# STM32F427 register map
File version: 1.7
CPU: CM4 r0p1, little endian, MPU, FPU, 4 interrupt priority bits
Registers are 32-bit, read-write, reset 0x0 unless marked. A register's access mark holds for its fields unless they carry their own. Offsets are from the block's base; [hi:lo] are bit positions; lines under a group give offsets from that group; {n}, {i} and the like mark numbered series.

## OTG_FS_PWRCLK — USB on the go full speed
Base 0x50000E00
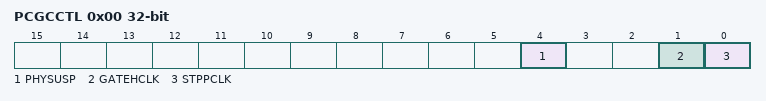
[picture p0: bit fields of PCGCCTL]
0x00 PCGCCTL — OTG_FS power and clock gating control register (OTG_FS_PCGCCTL)
  [4] PHYSUSP — PHY Suspended
  [1] GATEHCLK
  [0] STPPCLK — Stop PHY clock

## EXTI — External interrupt/event controller
Base 0x40013C00
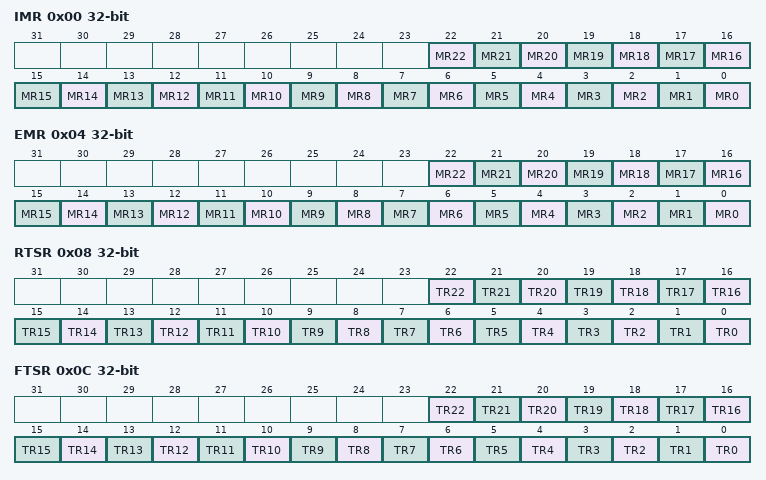
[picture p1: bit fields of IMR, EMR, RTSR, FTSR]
0x00 IMR — Interrupt mask register (EXTI_IMR)
  [n] MR{n} (n=0..22) — Interrupt Mask on line {n}
    0=Masked (Interrupt request line is masked); 1=Unmasked (Interrupt request line is unmasked)
0x04 EMR — Event mask register (EXTI_EMR)
  [n] MR{n} (n=0..22) — Event Mask on line {n}
    0=Masked (Event request line is masked); 1=Unmasked (Event request line is unmasked)
0x08 RTSR — Rising Trigger selection register (EXTI_RTSR)
  [n] TR{n} (n=0..22) — Rising trigger event configuration of line {n}
    0=Disabled (Rising edge trigger is disabled); 1=Enabled (Rising edge trigger is enabled)
0x0C FTSR — Falling Trigger selection register (EXTI_FTSR)
  [n] TR{n} (n=0..22) — Falling trigger event configuration of line {n}
    0=Disabled (Falling edge trigger is disabled); 1=Enabled (Falling edge trigger is enabled)
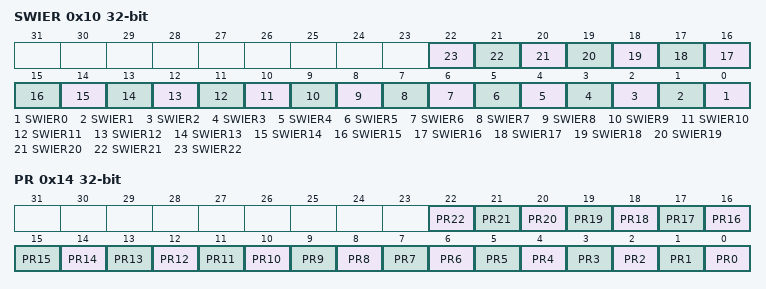
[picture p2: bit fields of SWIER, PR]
0x10 SWIER — Software interrupt event register (EXTI_SWIER)
  [n] SWIER{n} (n=0..22) — Software Interrupt on line {n}
    on write: 1=Pend (Generates an interrupt request)
0x14 PR — Pending register (EXTI_PR)
  [n] PR{n} (n=0..22) write-1-clears — Pending bit {n}
    on read: 0=NotPending (No trigger request occurred); 1=Pending (Selected trigger request occurred) | on write: 1=Clears pending bit

## OTG_HS_HOST — USB on the go high speed
Base 0x40040400
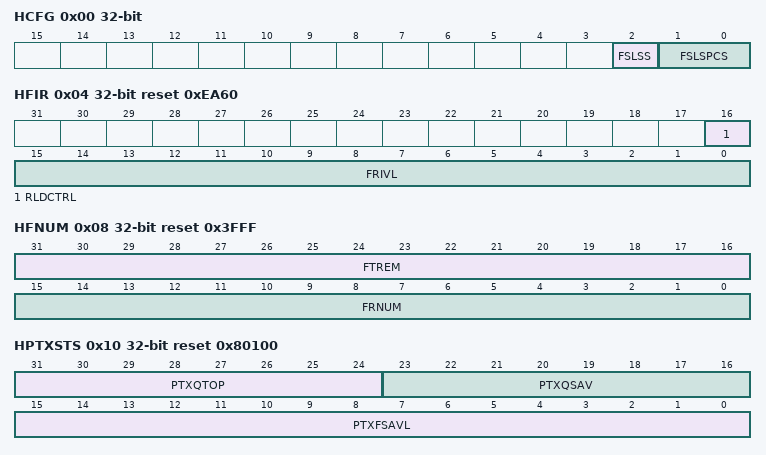
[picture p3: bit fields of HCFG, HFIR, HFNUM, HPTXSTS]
0x00 HCFG access per field — OTG_HS host configuration register
  [2] FSLSS ro — FS- and LS-only support
  [1:0] FSLSPCS rw — FS/LS PHY clock select
0x04 HFIR reset 0xEA60 — OTG_HS Host frame interval register
  [16] RLDCTRL — Reload control
  [15:0] FRIVL — Frame interval
0x08 HFNUM ro reset 0x3FFF — OTG_HS host frame number/frame time remaining register
  [31:16] FTREM — Frame time remaining
  [15:0] FRNUM — Frame number
0x10 HPTXSTS access per field reset 0x80100 — OTG_HS_Host periodic transmit FIFO/queue status register
  [31:24] PTXQTOP ro — Top of the periodic transmit request queue
  [23:16] PTXQSAV ro — Periodic transmit request queue space available
  [15:0] PTXFSAVL rw — Periodic transmit data FIFO space available
0x14 HAINT ro — OTG_HS Host all channels interrupt register
  [15:0] HAINT — Channel interrupts
0x18 HAINTMSK — OTG_HS host all channels interrupt mask register
  [15:0] HAINTM — Channel interrupt mask
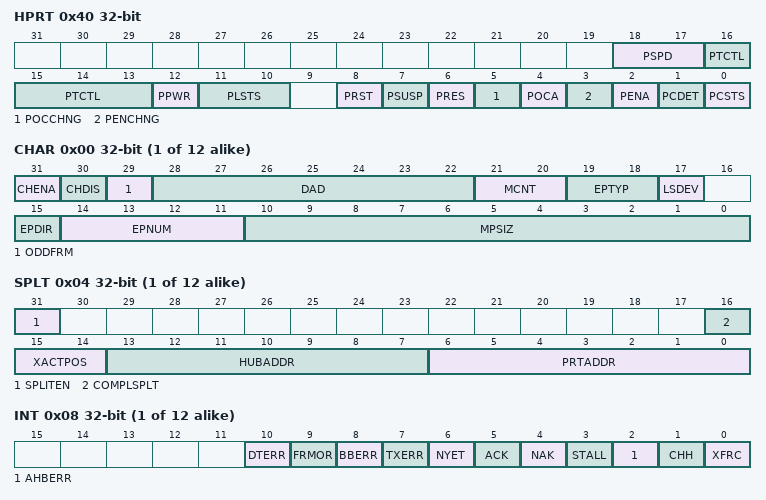
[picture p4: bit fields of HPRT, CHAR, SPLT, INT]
0x40 HPRT access per field — OTG_HS host port control and status register
  [18:17] PSPD ro — Port speed
  [16:13] PTCTL rw — Port test control
  [12] PPWR rw — Port power
  [11:10] PLSTS ro — Port line status
  [8] PRST rw — Port reset
  [7] PSUSP rw — Port suspend
  [6] PRES rw — Port resume
  [5] POCCHNG rw — Port overcurrent change
  [4] POCA ro — Port overcurrent active
  [3] PENCHNG rw — Port enable/disable change
  [2] PENA rw — Port enable
  [1] PCDET rw — Port connect detected
  [0] PCSTS ro — Port connect status
{0x100+0x20*i} HC{i} (i=0..11) group — Host channel
  0x00 CHAR — OTG_HS host channel-0 characteristics register
    [31] CHENA — Channel enable
    [30] CHDIS — Channel disable
    [29] ODDFRM — Odd frame
    [28:22] DAD — Device address
    [21:20] MCNT — Multi Count (MC) / Error Count (EC)
    [19:18] EPTYP — Endpoint type
    [17] LSDEV — Low-speed device
    [15] EPDIR — Endpoint direction
    [14:11] EPNUM — Endpoint number
    [10:0] MPSIZ — Maximum packet size
  0x04 SPLT — OTG_HS host channel-0 split control register
    [31] SPLITEN — Split enable
    [16] COMPLSPLT — Do complete split
    [15:14] XACTPOS
    [13:7] HUBADDR — Hub address
    [6:0] PRTADDR — Port address
  0x08 INT — OTG_HS host channel-11 interrupt register
    [10] DTERR — Data toggle error
    [9] FRMOR — Frame overrun
    [8] BBERR — Babble error
    [7] TXERR — Transaction error
    [6] NYET — Response received interrupt
    [5] ACK — ACK response received/transmitted interrupt
    [4] NAK — NAK response received interrupt
    [3] STALL — STALL response received interrupt
    [2] AHBERR — AHB error
    [1] CHH — Channel halted
    [0] XFRC — Transfer completed
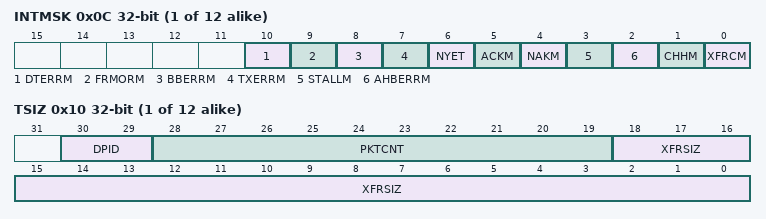
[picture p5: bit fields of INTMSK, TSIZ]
  0x0C INTMSK — OTG_HS host channel-11 interrupt mask register
    [10] DTERRM — Data toggle error mask
    [9] FRMORM — Frame overrun mask
    [8] BBERRM — Babble error mask
    [7] TXERRM — Transaction error mask
    [6] NYET — response received interrupt mask
    [5] ACKM — ACK response received/transmitted interrupt mask
    [4] NAKM — NAK response received interrupt mask
    [3] STALLM — STALL response received interrupt mask
    [2] AHBERRM — AHB error
    [1] CHHM — Channel halted mask
    [0] XFRCM — Transfer completed mask
  0x10 TSIZ — OTG_HS host channel-11 transfer size register
    [30:29] DPID — Data PID
    [28:19] PKTCNT — Packet count
    [18:0] XFRSIZ — Transfer size
  0x14 DMA — OTG_HS host channel-0 DMA address register
    [31:0] DMAADDR — DMA address

## OTG_HS_PWRCLK — USB on the go high speed
Base 0x40040E00
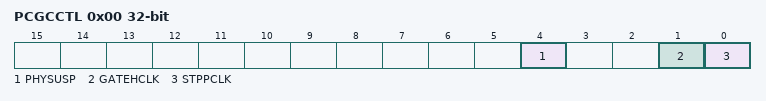
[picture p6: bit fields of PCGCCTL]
0x00 PCGCCTL — Power and clock gating control register
  [4] PHYSUSP — PHY suspended
  [1] GATEHCLK
  [0] STPPCLK — Stop PHY clock
